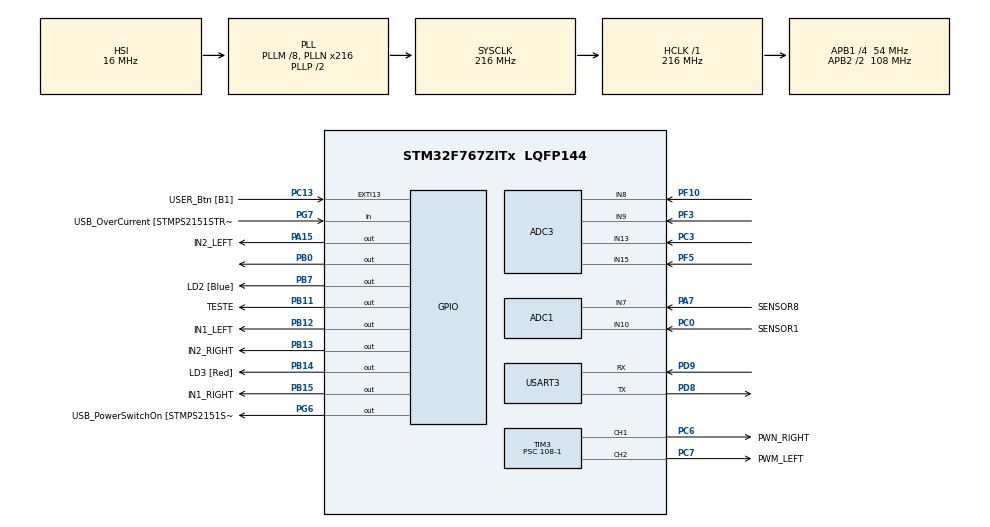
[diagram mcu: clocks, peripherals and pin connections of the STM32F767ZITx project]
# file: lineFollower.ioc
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Mcu.Family=STM32F7
NVIC.USART3_IRQn=true\:0\:0\:false\:false\:true\:true\:true
RCC.CortexFreq_Value=216000000
PG6.Signal=GPIO_Output
ADC1.ContinuousConvMode=ENABLE
NVIC.TIM6_DAC_IRQn=true\:0\:0\:false\:false\:true\:true\:true
ADC3.SamplingTime-7\#ChannelRegularConversion=ADC_SAMPLETIME_480CYCLES
PB14.GPIO_Label=LD3 [Red]
PG6.GPIO_Label=USB_PowerSwitchOn [STMPS2151STR_EN]
PA14.GPIO_Label=TCK
RCC.SYSCLKSourceVirtual=RCC_SYSCLKSOURCE_PLLCLK
PC0.GPIO_Label=SENSOR1
PC6.GPIO_Label=PWN_RIGHT
PC13.GPIO_Label=USER_Btn [B1]
PB13.GPIO_Label=IN2_RIGHT
PB11.Signal=GPIO_Output
PB13.Signal=GPIO_Output
PB15.Signal=GPIO_Output
PD9.Mode=Asynchronous
RCC.SYSCLKSource=RCC_SYSCLKSOURCE_PLLCLK
ProjectManager.StackSize=0x400
ADC3.Channel-6\#ChannelRegularConversion=ADC_CHANNEL_15
USART3.VirtualMode-Asynchronous=VM_ASYNC
VP_TIM7_VS_ClockSourceINT.Mode=Enable_Timer
ADC3.SamplingTime-4\#ChannelRegularConversion=ADC_SAMPLETIME_480CYCLES
Dma.ADC3.1.PeriphDataAlignment=DMA_PDATAALIGN_WORD
PA15.GPIO_Label=IN2_LEFT
ADC3.Rank-7\#ChannelRegularConversion=4
ADC1.Channel-3\#ChannelRegularConversion=ADC_CHANNEL_7
RCC.HCLKFreq_Value=216000000
RCC.APB2TimFreq_Value=216000000
TIM3.Period=100-0
Dma.ADC1.0.Direction=DMA_PERIPH_TO_MEMORY
ADC1.Channel-2\#ChannelRegularConversion=ADC_CHANNEL_10
PC7.Signal=S_TIM3_CH2
PC3.Signal=ADCx_IN13
ADC3.ScanConvMode=ADC_SCAN_ENABLE
TIM7.Period=20000-1
PD8.Signal=USART3_TX
NVIC.DMA2_Stream0_IRQn=true\:0\:0\:false\:false\:true\:false\:true
Dma.ADC1.0.MemDataAlignment=DMA_MDATAALIGN_WORD
RCC.AHBFreq_Value=216000000
TIM3.Channel-PWM\ Generation1\ CH1=TIM_CHANNEL_1
RCC.HSE_VALUE=16000000
RCC.PLLMUL=RCC_PLL_MUL9
PB12.GPIO_Label=IN1_LEFT
ADC1.Rank-2\#ChannelRegularConversion=1
PA14.Mode=Serial_Wire
ADC3.SamplingTime-5\#ChannelRegularConversion=ADC_SAMPLETIME_480CYCLES
TIM3.Prescaler=108-1
Dma.ADC1.0.PeriphInc=DMA_PINC_DISABLE
PB7.Signal=GPIO_Output
SH.S_TIM3_CH1.0=TIM3_CH1,PWM Generation1 CH1
TIM6.Period=100-1
PF3.Signal=ADC3_IN9
TIM7.TIM_MasterOutputTrigger=TIM_TRGO_UPDATE
ADC3.Rank-4\#ChannelRegularConversion=1
PB7.GPIO_Label=LD2 [Blue]
Mcu.Package=LQFP144
Dma.ADC3.1.Direction=DMA_PERIPH_TO_MEMORY
PA15.Signal=GPIO_Output
PF5.Signal=ADC3_IN15
ADC3.DMAContinuousRequests=ENABLE
RCC.APB2CLKDivider=RCC_HCLK_DIV2
Dma.Request1=ADC3
RCC.APB1TimFreq_Value=108000000
Dma.ADC1.0.FIFOMode=DMA_FIFOMODE_DISABLE
PF10.Mode=IN8
Dma.Request0=ADC1
Dma.ADC3.1.Priority=DMA_PRIORITY_LOW
NVIC.TIM7_IRQn=true\:0\:0\:false\:false\:true\:true\:true
VP_TIM3_VS_ClockSourceINT.Mode=Internal
ADC3.Channel-7\#ChannelRegularConversion=ADC_CHANNEL_8
SH.ADCx_IN13.0=ADC3_IN13,IN13
Dma.ADC1.0.Instance=DMA2_Stream0
PG7.Signal=GPIO_Input
PF3.Mode=IN9
TIM3.AutoReloadPreload=TIM_AUTORELOAD_PRELOAD_ENABLE
PC13.Signal=GPXTI13
ADC3.Rank-6\#ChannelRegularConversion=3
TIM6.Prescaler=10800-1
PC6.Signal=S_TIM3_CH1
VP_TIM6_VS_ClockSourceINT.Mode=Enable_Timer
PB11.GPIO_Label=TESTE
PD9.Signal=USART3_RX
NVIC.DMA2_Stream1_IRQn=true\:0\:0\:false\:false\:true\:false\:true
PC0.Signal=ADCx_IN10
RCC.APB1CLKDivider=RCC_HCLK_DIV4
PF5.Mode=IN15
ADC1.SamplingTime-2\#ChannelRegularConversion=ADC_SAMPLETIME_480CYCLES
PA13.Signal=SYS_JTMS-SWDIO
Dma.ADC1.0.PeriphDataAlignment=DMA_PDATAALIGN_WORD
ProjectManager.TargetToolchain=STM32CubeIDE
ADC3.Channel-4\#ChannelRegularConversion=ADC_CHANNEL_13
SH.ADCx_IN7.0=ADC1_IN7,IN7
Dma.ADC1.0.Mode=DMA_CIRCULAR
ADC3.SamplingTime-6\#ChannelRegularConversion=ADC_SAMPLETIME_480CYCLES
Dma.ADC1.0.Priority=DMA_PRIORITY_LOW
RCC.USBFreq_Value=216000000
ADC3.NbrOfConversion=4
Dma.ADC3.1.FIFOMode=DMA_FIFOMODE_DISABLE
RCC.LSE_VALUE=32768
PD8.Mode=Asynchronous
Dma.ADC3.1.Instance=DMA2_Stream1
PB14.Signal=GPIO_Output
SH.S_TIM3_CH2.0=TIM3_CH2,PWM Generation2 CH2
TIM7.Prescaler=10800-1
board=NUCLEO-F767ZI
RCC.VCOOutputFreq_Value=432000000
NVIC.TIM3_IRQn=true\:0\:0\:false\:false\:true\:true\:true
RCC.APB2Freq_Value=108000000
ADC3.Channel-5\#ChannelRegularConversion=ADC_CHANNEL_9
RCC.PRESCALERUSB=RCC_USBCLKSOURCE_PLL_DIV1_5
PB15.GPIO_Label=IN1_RIGHT
PG7.GPIO_Label=USB_OverCurrent [STMPS2151STR_FAULT]
PF10.Signal=ADC3_IN8
Dma.ADC3.1.MemDataAlignment=DMA_MDATAALIGN_WORD
TIM6.TIM_MasterOutputTrigger=TIM_TRGO_UPDATE
Dma.ADC3.1.MemInc=DMA_MINC_ENABLE
Dma.ADC3.1.PeriphInc=DMA_PINC_DISABLE
ADC1.DMAContinuousRequests=ENABLE
ADC3.Rank-5\#ChannelRegularConversion=2
ADC1.NbrOfConversion=2
PA13.Mode=Serial_Wire
Dma.ADC3.1.Mode=DMA_CIRCULAR
Mcu.Name=STM32F767ZITx
PC7.GPIO_Label=PWM_LEFT
RCC.48MHZClocksFreq_Value=24000000
RCC.SYSCLKFreq_VALUE=216000000
ADC1.master=1
PA7.GPIO_Label=SENSOR8
ADC1.Rank-3\#ChannelRegularConversion=2
ADC1.SamplingTime-3\#ChannelRegularConversion=ADC_SAMPLETIME_480CYCLES
PA14.Signal=SYS_JTCK-SWCLK
Dma.ADC1.0.MemInc=DMA_MINC_ENABLE
SH.ADCx_IN10.0=ADC1_IN10,IN10
ProjectManager.HeapSize=0x200
RCC.HSI_VALUE=16000000
NVIC.PriorityGroup=NVIC_PRIORITYGROUP_4
ADC1.NbrOfConversionFlag=1
TIM3.Channel-PWM\ Generation2\ CH2=TIM_CHANNEL_2
RCC.PLLM=8
RCC.PLLN=216
RCC.APB1Freq_Value=54000000
ADC3.NbrOfConversionFlag=1
PB0.Signal=GPIO_Output
PB12.Signal=GPIO_Output
PA7.Signal=ADCx_IN7

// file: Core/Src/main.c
/* USER CODE BEGIN Header */
/**
  ******************************************************************************
  * @file           : main.c
  * @brief          : Main program body
  ******************************************************************************
  * @attention
  *
  * <h2><center>&copy; Copyright (c) 2021 STMicroelectronics.
  * All rights reserved.</center></h2>
  *
  * This software component is licensed by ST under BSD 3-Clause license,
  * the "License"; You may not use this file except in compliance with the
  * License. You may obtain a copy of the License at:
  *                        opensource.org/licenses/BSD-3-Clause
  *
  ******************************************************************************
  */
/* USER CODE END Header */
#include "main.h"
#include "adc.h"
#include "dma.h"
#include "tim.h"
#include "usart.h"
#include "gpio.h"

/* USER CODE BEGIN Includes */
#include "tests.h"

#include "move.h"
#include "lfollower.h"

/* USER CODE END Includes */

void SystemClock_Config(void);

int main(void)
{

  /* MCU Configuration--------------------------------------------------------*/

  /* Reset of all peripherals, Initializes the Flash interface and the Systick. */
  HAL_Init();

  /* Configure the system clock */
  SystemClock_Config();

  /* Initialize all configured peripherals */
  MX_GPIO_Init();
  MX_DMA_Init();
  MX_ADC1_Init();
  MX_TIM6_Init();
  MX_TIM3_Init();
  MX_USART3_UART_Init();
  MX_ADC3_Init();
  MX_TIM7_Init();

  /* Infinite loop */
  /* USER CODE BEGIN WHILE */

  // inits motors, PID and DMA to sensors
  //lfollower_start();
  lfollower_start();
   while (1)
  {
	   //lfollower_start();
	   //move_forward(0.7);

		//  ------ test move module ------
		//test_move(0.9);
		// test saturation
		// test_move(-1);

	  // ------- test line follower module -------
	  //lfollower_pid();
	  //HAL_Delay(1000);

	   //lfollower_stop();

	   //test_lfollower(MOVE_RIGHT);

	  //break;

    /* USER CODE END WHILE */

  }
}

void SystemClock_Config(void)
{
  RCC_OscInitTypeDef RCC_OscInitStruct = {0};
  RCC_ClkInitTypeDef RCC_ClkInitStruct = {0};
  RCC_PeriphCLKInitTypeDef PeriphClkInitStruct = {0};

  /** Configure the main internal regulator output voltage
  */
  __HAL_RCC_PWR_CLK_ENABLE();
  __HAL_PWR_VOLTAGESCALING_CONFIG(PWR_REGULATOR_VOLTAGE_SCALE1);
  /** Initializes the RCC Oscillators according to the specified parameters
  * in the RCC_OscInitTypeDef structure.
  */
  RCC_OscInitStruct.OscillatorType = RCC_OSCILLATORTYPE_HSI;
  RCC_OscInitStruct.HSIState = RCC_HSI_ON;
  RCC_OscInitStruct.HSICalibrationValue = RCC_HSICALIBRATION_DEFAULT;
  RCC_OscInitStruct.PLL.PLLState = RCC_PLL_ON;
  RCC_OscInitStruct.PLL.PLLSource = RCC_PLLSOURCE_HSI;
  RCC_OscInitStruct.PLL.PLLM = 8;
  RCC_OscInitStruct.PLL.PLLN = 216;
  RCC_OscInitStruct.PLL.PLLP = RCC_PLLP_DIV2;
  RCC_OscInitStruct.PLL.PLLQ = 2;
  if (HAL_RCC_OscConfig(&RCC_OscInitStruct) != HAL_OK)
  {
    Error_Handler();
  }
  /** Activate the Over-Drive mode
  */
  if (HAL_PWREx_EnableOverDrive() != HAL_OK)
  {
    Error_Handler();
  }
  /** Initializes the CPU, AHB and APB buses clocks
  */
  RCC_ClkInitStruct.ClockType = RCC_CLOCKTYPE_HCLK|RCC_CLOCKTYPE_SYSCLK
                              |RCC_CLOCKTYPE_PCLK1|RCC_CLOCKTYPE_PCLK2;
  RCC_ClkInitStruct.SYSCLKSource = RCC_SYSCLKSOURCE_PLLCLK;
  RCC_ClkInitStruct.AHBCLKDivider = RCC_SYSCLK_DIV1;
  RCC_ClkInitStruct.APB1CLKDivider = RCC_HCLK_DIV4;
  RCC_ClkInitStruct.APB2CLKDivider = RCC_HCLK_DIV2;

  if (HAL_RCC_ClockConfig(&RCC_ClkInitStruct, FLASH_LATENCY_7) != HAL_OK)
  {
    Error_Handler();
  }
  PeriphClkInitStruct.PeriphClockSelection = RCC_PERIPHCLK_USART3;
  PeriphClkInitStruct.Usart3ClockSelection = RCC_USART3CLKSOURCE_PCLK1;
  if (HAL_RCCEx_PeriphCLKConfig(&PeriphClkInitStruct) != HAL_OK)
  {
    Error_Handler();
  }
}

void Error_Handler(void)
{
  __disable_irq();
  while (1)
  {
  }
}

/************************ (C) COPYRIGHT STMicroelectronics *****END OF FILE****/
